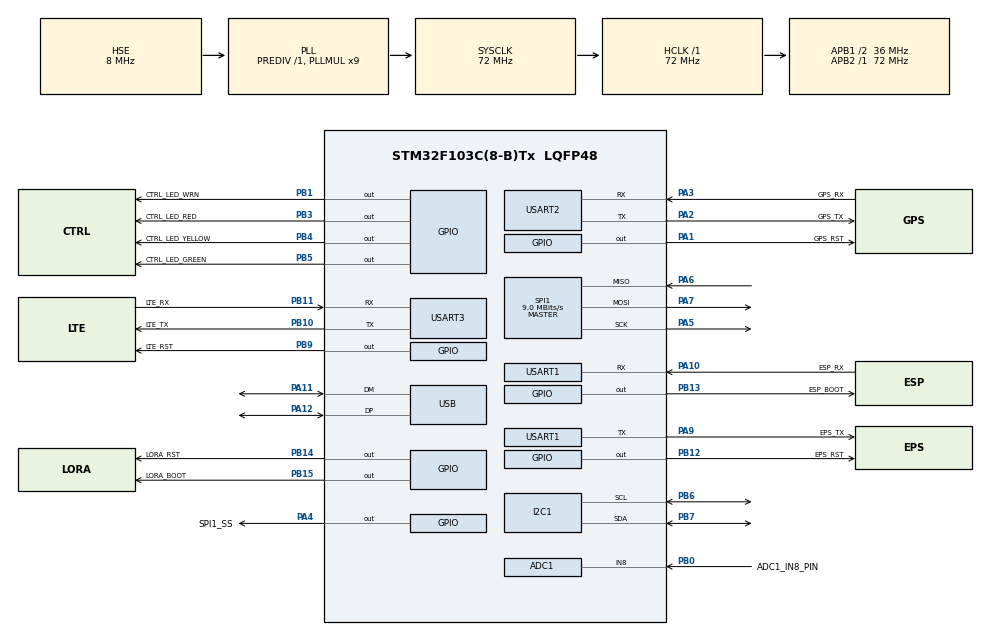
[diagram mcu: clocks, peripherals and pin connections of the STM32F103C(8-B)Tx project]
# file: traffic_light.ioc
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ADC1.Channel-1\#ChannelRegularConversion=ADC_CHANNEL_8
ADC1.NbrOfConversionFlag=1
ADC1.Rank-1\#ChannelRegularConversion=1
ADC1.SamplingTime-1\#ChannelRegularConversion=ADC_SAMPLETIME_239CYCLES_5
ADC1.master=1
Mcu.Family=STM32F1
Mcu.Name=STM32F103C(8-B)Tx
Mcu.Package=LQFP48
NVIC.I2C1_ER_IRQn=true\:0\:0\:false\:false\:true\:true\:true\:true
NVIC.I2C1_EV_IRQn=true\:0\:0\:false\:false\:true\:true\:true\:true
NVIC.PriorityGroup=NVIC_PRIORITYGROUP_4
NVIC.SPI1_IRQn=true\:0\:0\:false\:false\:true\:true\:true\:true
NVIC.TIM2_IRQn=true\:0\:0\:false\:false\:true\:true\:true\:true
NVIC.USART1_IRQn=true\:0\:0\:false\:false\:true\:true\:true\:true
NVIC.USART2_IRQn=true\:0\:0\:false\:false\:true\:true\:true\:true
NVIC.USART3_IRQn=true\:0\:0\:false\:false\:true\:true\:true\:true
NVIC.USB_HP_CAN1_TX_IRQn=true\:0\:0\:false\:false\:true\:true\:true\:true
NVIC.USB_LP_CAN1_RX0_IRQn=true\:0\:0\:false\:false\:true\:true\:true\:true
PA1.GPIO_Label=GPS_RST
PA1.Signal=GPIO_Output
PA10.GPIO_Label=ESP_RX
PA10.Mode=Asynchronous
PA10.Signal=USART1_RX
PA11.Mode=Device
PA11.Signal=USB_DM
PA12.Mode=Device
PA12.Signal=USB_DP
PA13.Mode=Serial_Wire
PA13.Signal=SYS_JTMS-SWDIO
PA14.Mode=Serial_Wire
PA14.Signal=SYS_JTCK-SWCLK
PA2.GPIO_Label=GPS_TX
PA2.Mode=Asynchronous
PA2.Signal=USART2_TX
PA3.GPIO_Label=GPS_RX
PA3.Mode=Asynchronous
PA3.Signal=USART2_RX
PA4.GPIO_Label=SPI1_SS
PA4.Signal=GPIO_Output
PA5.Mode=Full_Duplex_Master
PA5.Signal=SPI1_SCK
PA6.Mode=Full_Duplex_Master
PA6.Signal=SPI1_MISO
PA7.Mode=Full_Duplex_Master
PA7.Signal=SPI1_MOSI
PA9.GPIO_Label=EPS_TX
PA9.Mode=Asynchronous
PA9.Signal=USART1_TX
PB0.GPIO_Label=ADC1_IN8_PIN
PB0.Signal=ADCx_IN8
PB1.GPIO_Label=CTRL_LED_WRN
PB1.Signal=GPIO_Output
PB10.GPIO_Label=LTE_TX
PB10.Mode=Asynchronous
PB10.Signal=USART3_TX
PB11.GPIO_Label=LTE_RX
PB11.Mode=Asynchronous
PB11.Signal=USART3_RX
PB12.GPIO_Label=EPS_RST
PB12.Signal=GPIO_Output
PB13.GPIO_Label=ESP_BOOT
PB13.Signal=GPIO_Output
PB14.GPIO_Label=LORA_RST
PB14.Signal=GPIO_Output
PB15.GPIO_Label=LORA_BOOT
PB15.Signal=GPIO_Output
PB3.GPIO_Label=CTRL_LED_RED
PB3.Signal=GPIO_Output
PB4.GPIO_Label=CTRL_LED_YELLOW
PB4.Signal=GPIO_Output
PB5.GPIO_Label=CTRL_LED_GREEN
PB5.Signal=GPIO_Output
PB6.Mode=I2C
PB6.Signal=I2C1_SCL
PB7.Mode=I2C
PB7.Signal=I2C1_SDA
PB9.GPIO_Label=LTE_RST
PB9.Signal=GPIO_Output
PD0-OSC_IN.Mode=HSE-External-Oscillator
PD0-OSC_IN.Signal=RCC_OSC_IN
PD1-OSC_OUT.Mode=HSE-External-Oscillator
PD1-OSC_OUT.Signal=RCC_OSC_OUT
ProjectManager.HeapSize=0x200
ProjectManager.StackSize=0x400
ProjectManager.TargetToolchain=STM32CubeIDE
RCC.ADCPresc=RCC_ADCPCLK2_DIV6
RCC.AHBFreq_Value=72000000
RCC.APB1CLKDivider=RCC_HCLK_DIV2
RCC.APB1Freq_Value=36000000
RCC.APB1TimFreq_Value=72000000
RCC.APB2Freq_Value=72000000
RCC.APB2TimFreq_Value=72000000
RCC.HCLKFreq_Value=72000000
RCC.PLLMUL=RCC_PLL_MUL9
RCC.PLLSourceVirtual=RCC_PLLSOURCE_HSE
RCC.SYSCLKFreq_VALUE=72000000
RCC.SYSCLKSource=RCC_SYSCLKSOURCE_PLLCLK
RCC.USBFreq_Value=48000000
RCC.USBPrescaler=RCC_USBCLKSOURCE_PLL_DIV1_5
SH.ADCx_IN8.0=ADC1_IN8,IN8
SPI1.BaudRatePrescaler=SPI_BAUDRATEPRESCALER_8
SPI1.CalculateBaudRate=9.0 MBits/s
SPI1.Direction=SPI_DIRECTION_2LINES
SPI1.Mode=SPI_MODE_MASTER
SPI1.VirtualType=VM_MASTER
TIM2.AutoReloadPreload=TIM_AUTORELOAD_PRELOAD_ENABLE
TIM2.Period=999
TIM2.Prescaler=71
USART1.VirtualMode=VM_ASYNC
USART2.VirtualMode=VM_ASYNC
USART3.VirtualMode=VM_ASYNC
USB_DEVICE.APP_RX_DATA_SIZE=512
USB_DEVICE.APP_TX_DATA_SIZE=512
USB_DEVICE.CLASS_NAME_FS=CDC
USB_DEVICE.VirtualMode=Cdc
USB_DEVICE.VirtualModeFS=Cdc_FS
VP_TIM2_VS_ClockSourceINT.Mode=Internal
VP_USB_DEVICE_VS_USB_DEVICE_CDC_FS.Mode=CDC_FS
board=custom

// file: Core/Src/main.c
/* USER CODE BEGIN Header */
/**
  ******************************************************************************
  * @file           : main.c
  * @brief          : Main program body
  ******************************************************************************
  * @attention
  *
  * Copyright (c) 2024 STMicroelectronics.
  * All rights reserved.
  *
  * This software is licensed under terms that can be found in the LICENSE file
  * in the root directory of this software component.
  * If no LICENSE file comes with this software, it is provided AS-IS.
  *
  ******************************************************************************
  */
/* USER CODE END Header */
#include "main.h"
#include "usb_device.h"

ADC_HandleTypeDef hadc1;

I2C_HandleTypeDef hi2c1;

SPI_HandleTypeDef hspi1;

TIM_HandleTypeDef htim2;

UART_HandleTypeDef huart1;
UART_HandleTypeDef huart2;
UART_HandleTypeDef huart3;

void SystemClock_Config(void);
static void MX_GPIO_Init(void);
static void MX_ADC1_Init(void);
static void MX_I2C1_Init(void);
static void MX_SPI1_Init(void);
static void MX_TIM2_Init(void);
static void MX_USART1_UART_Init(void);
static void MX_USART2_UART_Init(void);
static void MX_USART3_UART_Init(void);
/* USER CODE BEGIN PFP */
void main_app();
/* USER CODE END PFP */

int main(void)
{

  /* MCU Configuration--------------------------------------------------------*/

  /* Reset of all peripherals, Initializes the Flash interface and the Systick. */
  HAL_Init();

  /* Configure the system clock */
  SystemClock_Config();

  /* Initialize all configured peripherals */
  MX_GPIO_Init();
  MX_ADC1_Init();
  MX_I2C1_Init();
  MX_SPI1_Init();
  MX_TIM2_Init();
  MX_USART1_UART_Init();
  MX_USART2_UART_Init();
  MX_USART3_UART_Init();
  MX_USB_DEVICE_Init();

  /* Infinite loop */
  /* USER CODE BEGIN WHILE */
  main_app();
  while (1)
  {
    /* USER CODE END WHILE */

  }
}

void SystemClock_Config(void)
{
  RCC_OscInitTypeDef RCC_OscInitStruct = {0};
  RCC_ClkInitTypeDef RCC_ClkInitStruct = {0};
  RCC_PeriphCLKInitTypeDef PeriphClkInit = {0};

  /** Initializes the RCC Oscillators according to the specified parameters
  * in the RCC_OscInitTypeDef structure.
  */
  RCC_OscInitStruct.OscillatorType = RCC_OSCILLATORTYPE_HSE;
  RCC_OscInitStruct.HSEState = RCC_HSE_ON;
  RCC_OscInitStruct.HSEPredivValue = RCC_HSE_PREDIV_DIV1;
  RCC_OscInitStruct.HSIState = RCC_HSI_ON;
  RCC_OscInitStruct.PLL.PLLState = RCC_PLL_ON;
  RCC_OscInitStruct.PLL.PLLSource = RCC_PLLSOURCE_HSE;
  RCC_OscInitStruct.PLL.PLLMUL = RCC_PLL_MUL9;
  if (HAL_RCC_OscConfig(&RCC_OscInitStruct) != HAL_OK)
  {
    Error_Handler();
  }

  /** Initializes the CPU, AHB and APB buses clocks
  */
  RCC_ClkInitStruct.ClockType = RCC_CLOCKTYPE_HCLK|RCC_CLOCKTYPE_SYSCLK
                              |RCC_CLOCKTYPE_PCLK1|RCC_CLOCKTYPE_PCLK2;
  RCC_ClkInitStruct.SYSCLKSource = RCC_SYSCLKSOURCE_PLLCLK;
  RCC_ClkInitStruct.AHBCLKDivider = RCC_SYSCLK_DIV1;
  RCC_ClkInitStruct.APB1CLKDivider = RCC_HCLK_DIV2;
  RCC_ClkInitStruct.APB2CLKDivider = RCC_HCLK_DIV1;

  if (HAL_RCC_ClockConfig(&RCC_ClkInitStruct, FLASH_LATENCY_2) != HAL_OK)
  {
    Error_Handler();
  }
  PeriphClkInit.PeriphClockSelection = RCC_PERIPHCLK_ADC|RCC_PERIPHCLK_USB;
  PeriphClkInit.AdcClockSelection = RCC_ADCPCLK2_DIV6;
  PeriphClkInit.UsbClockSelection = RCC_USBCLKSOURCE_PLL_DIV1_5;
  if (HAL_RCCEx_PeriphCLKConfig(&PeriphClkInit) != HAL_OK)
  {
    Error_Handler();
  }
}

static void MX_ADC1_Init(void)
{

  ADC_ChannelConfTypeDef sConfig = {0};

  /** Common config
  */
  hadc1.Instance = ADC1;
  hadc1.Init.ScanConvMode = ADC_SCAN_DISABLE;
  hadc1.Init.ContinuousConvMode = DISABLE;
  hadc1.Init.DiscontinuousConvMode = DISABLE;
  hadc1.Init.ExternalTrigConv = ADC_SOFTWARE_START;
  hadc1.Init.DataAlign = ADC_DATAALIGN_RIGHT;
  hadc1.Init.NbrOfConversion = 1;
  if (HAL_ADC_Init(&hadc1) != HAL_OK)
  {
    Error_Handler();
  }

  /** Configure Regular Channel
  */
  sConfig.Channel = ADC_CHANNEL_8;
  sConfig.Rank = ADC_REGULAR_RANK_1;
  sConfig.SamplingTime = ADC_SAMPLETIME_239CYCLES_5;
  if (HAL_ADC_ConfigChannel(&hadc1, &sConfig) != HAL_OK)
  {
    Error_Handler();
  }

}

static void MX_I2C1_Init(void)
{

  hi2c1.Instance = I2C1;
  hi2c1.Init.ClockSpeed = 100000;
  hi2c1.Init.DutyCycle = I2C_DUTYCYCLE_2;
  hi2c1.Init.OwnAddress1 = 0;
  hi2c1.Init.AddressingMode = I2C_ADDRESSINGMODE_7BIT;
  hi2c1.Init.DualAddressMode = I2C_DUALADDRESS_DISABLE;
  hi2c1.Init.OwnAddress2 = 0;
  hi2c1.Init.GeneralCallMode = I2C_GENERALCALL_DISABLE;
  hi2c1.Init.NoStretchMode = I2C_NOSTRETCH_DISABLE;
  if (HAL_I2C_Init(&hi2c1) != HAL_OK)
  {
    Error_Handler();
  }

}

static void MX_SPI1_Init(void)
{

  /* SPI1 parameter configuration*/
  hspi1.Instance = SPI1;
  hspi1.Init.Mode = SPI_MODE_MASTER;
  hspi1.Init.Direction = SPI_DIRECTION_2LINES;
  hspi1.Init.DataSize = SPI_DATASIZE_8BIT;
  hspi1.Init.CLKPolarity = SPI_POLARITY_LOW;
  hspi1.Init.CLKPhase = SPI_PHASE_1EDGE;
  hspi1.Init.NSS = SPI_NSS_SOFT;
  hspi1.Init.BaudRatePrescaler = SPI_BAUDRATEPRESCALER_8;
  hspi1.Init.FirstBit = SPI_FIRSTBIT_MSB;
  hspi1.Init.TIMode = SPI_TIMODE_DISABLE;
  hspi1.Init.CRCCalculation = SPI_CRCCALCULATION_DISABLE;
  hspi1.Init.CRCPolynomial = 10;
  if (HAL_SPI_Init(&hspi1) != HAL_OK)
  {
    Error_Handler();
  }

}

static void MX_TIM2_Init(void)
{

  TIM_ClockConfigTypeDef sClockSourceConfig = {0};
  TIM_MasterConfigTypeDef sMasterConfig = {0};

  htim2.Instance = TIM2;
  htim2.Init.Prescaler = 71;
  htim2.Init.CounterMode = TIM_COUNTERMODE_UP;
  htim2.Init.Period = 999;
  htim2.Init.ClockDivision = TIM_CLOCKDIVISION_DIV1;
  htim2.Init.AutoReloadPreload = TIM_AUTORELOAD_PRELOAD_ENABLE;
  if (HAL_TIM_Base_Init(&htim2) != HAL_OK)
  {
    Error_Handler();
  }
  sClockSourceConfig.ClockSource = TIM_CLOCKSOURCE_INTERNAL;
  if (HAL_TIM_ConfigClockSource(&htim2, &sClockSourceConfig) != HAL_OK)
  {
    Error_Handler();
  }
  sMasterConfig.MasterOutputTrigger = TIM_TRGO_RESET;
  sMasterConfig.MasterSlaveMode = TIM_MASTERSLAVEMODE_DISABLE;
  if (HAL_TIMEx_MasterConfigSynchronization(&htim2, &sMasterConfig) != HAL_OK)
  {
    Error_Handler();
  }

}

static void MX_USART1_UART_Init(void)
{

  huart1.Instance = USART1;
  huart1.Init.BaudRate = 115200;
  huart1.Init.WordLength = UART_WORDLENGTH_8B;
  huart1.Init.StopBits = UART_STOPBITS_1;
  huart1.Init.Parity = UART_PARITY_NONE;
  huart1.Init.Mode = UART_MODE_TX_RX;
  huart1.Init.HwFlowCtl = UART_HWCONTROL_NONE;
  huart1.Init.OverSampling = UART_OVERSAMPLING_16;
  if (HAL_UART_Init(&huart1) != HAL_OK)
  {
    Error_Handler();
  }

}

static void MX_USART2_UART_Init(void)
{

  huart2.Instance = USART2;
  huart2.Init.BaudRate = 115200;
  huart2.Init.WordLength = UART_WORDLENGTH_8B;
  huart2.Init.StopBits = UART_STOPBITS_1;
  huart2.Init.Parity = UART_PARITY_NONE;
  huart2.Init.Mode = UART_MODE_TX_RX;
  huart2.Init.HwFlowCtl = UART_HWCONTROL_NONE;
  huart2.Init.OverSampling = UART_OVERSAMPLING_16;
  if (HAL_UART_Init(&huart2) != HAL_OK)
  {
    Error_Handler();
  }

}

static void MX_USART3_UART_Init(void)
{

  huart3.Instance = USART3;
  huart3.Init.BaudRate = 115200;
  huart3.Init.WordLength = UART_WORDLENGTH_8B;
  huart3.Init.StopBits = UART_STOPBITS_1;
  huart3.Init.Parity = UART_PARITY_NONE;
  huart3.Init.Mode = UART_MODE_TX_RX;
  huart3.Init.HwFlowCtl = UART_HWCONTROL_NONE;
  huart3.Init.OverSampling = UART_OVERSAMPLING_16;
  if (HAL_UART_Init(&huart3) != HAL_OK)
  {
    Error_Handler();
  }

}

static void MX_GPIO_Init(void)
{
  GPIO_InitTypeDef GPIO_InitStruct = {0};

  /* GPIO Ports Clock Enable */
  __HAL_RCC_GPIOD_CLK_ENABLE();
  __HAL_RCC_GPIOA_CLK_ENABLE();
  __HAL_RCC_GPIOB_CLK_ENABLE();

  /*Configure GPIO pin Output Level */
  HAL_GPIO_WritePin(GPIOA, GPS_RST_Pin|SPI1_SS_Pin, GPIO_PIN_RESET);

  /*Configure GPIO pin Output Level */
  HAL_GPIO_WritePin(GPIOB, CTRL_LED_WRN_Pin|EPS_RST_Pin|ESP_BOOT_Pin|LORA_RST_Pin
                          |LORA_BOOT_Pin|CTRL_LED_RED_Pin|CTRL_LED_YELLOW_Pin|CTRL_LED_GREEN_Pin
                          |LTE_RST_Pin, GPIO_PIN_RESET);

  /*Configure GPIO pins : GPS_RST_Pin SPI1_SS_Pin */
  GPIO_InitStruct.Pin = GPS_RST_Pin|SPI1_SS_Pin;
  GPIO_InitStruct.Mode = GPIO_MODE_OUTPUT_PP;
  GPIO_InitStruct.Pull = GPIO_NOPULL;
  GPIO_InitStruct.Speed = GPIO_SPEED_FREQ_LOW;
  HAL_GPIO_Init(GPIOA, &GPIO_InitStruct);

  /*Configure GPIO pins : CTRL_LED_WRN_Pin EPS_RST_Pin ESP_BOOT_Pin LORA_RST_Pin
                           LORA_BOOT_Pin CTRL_LED_RED_Pin CTRL_LED_YELLOW_Pin CTRL_LED_GREEN_Pin
                           LTE_RST_Pin */
  GPIO_InitStruct.Pin = CTRL_LED_WRN_Pin|EPS_RST_Pin|ESP_BOOT_Pin|LORA_RST_Pin
                          |LORA_BOOT_Pin|CTRL_LED_RED_Pin|CTRL_LED_YELLOW_Pin|CTRL_LED_GREEN_Pin
                          |LTE_RST_Pin;
  GPIO_InitStruct.Mode = GPIO_MODE_OUTPUT_PP;
  GPIO_InitStruct.Pull = GPIO_NOPULL;
  GPIO_InitStruct.Speed = GPIO_SPEED_FREQ_LOW;
  HAL_GPIO_Init(GPIOB, &GPIO_InitStruct);

}

void Error_Handler(void)
{
  __disable_irq();
  while (1)
  {
  }
}
